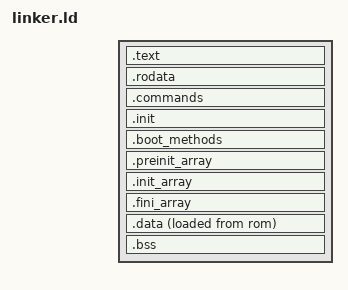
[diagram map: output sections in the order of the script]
INCLUDE generated/output_format.ld
ENTRY(_start)

INCLUDE generated/regions.ld

SECTIONS
{
	.text :
	{
		_ftext = .;
		/* ARM (Quicklogic EOS-S3, Gowin EMCU) interrupt vector tables use section name "isr_vector" */
		/* - such a table has to be placed at start */
		KEEP(*(.isr_vector))
		/* Make sure crt0 files come first, and they, and the isr */
		/* don't get disposed of by greedy optimisation */
		*crt0*(.text)
		KEEP(*crt0*(.text))
		KEEP(*(.text.isr))

		*(.text .stub .text.* .gnu.linkonce.t.*)
		_etext = .;
	} > rom

	.rodata :
	{
		. = ALIGN(8);
		_frodata = .;
		*(.rodata .rodata.* .gnu.linkonce.r.*)
		*(.rodata1)
		*(.srodata .srodata.*)
		*(.got .got.*)
		*(.toc .toc.*)

		/* Make sure the file is aligned on disk as well
		   as in memory; CRC calculation requires that. */
		FILL(0);
		. = ALIGN(8);
		_erodata = .;
	} > rom

	.commands :
	{
		PROVIDE_HIDDEN (__bios_cmd_start = .);
		KEEP(*(.bios_cmd))
		PROVIDE_HIDDEN (__bios_cmd_end = .);
	} > rom

	.init :
	{
		PROVIDE_HIDDEN (__bios_init_start = .);
		KEEP(*(.bios_init))
		PROVIDE_HIDDEN (__bios_init_end = .);
	} > rom

	.boot_methods :
	{
		PROVIDE_HIDDEN (__bios_boot_start = .);
		KEEP(*(.bios_boot))
		PROVIDE_HIDDEN (__bios_boot_end = .);
	} > rom

	.preinit_array :
	{
		. = ALIGN(8);
		PROVIDE_HIDDEN (__preinit_array_start = .);
		KEEP(*(SORT(.preinit_array.*)))
		KEEP(*(.preinit_array))
		PROVIDE_HIDDEN (__preinit_array_end = .);
	} > rom

	.init_array :
	{
		. = ALIGN(8);
		PROVIDE_HIDDEN (__init_array_start = .);
		KEEP(*(SORT(.init_array.*)))
		KEEP(*(.init_array))
		KEEP(*(SORT(.ctors.*)))
		KEEP(*(.ctors))
		PROVIDE_HIDDEN (__init_array_end = .);
	} > rom

	.fini_array :
	{
		. = ALIGN(8);
		PROVIDE_HIDDEN (__fini_array_start = .);
		KEEP(*(SORT(.fini_array.*)))
		KEEP(*(.fini_array))
		KEEP(*(SORT(.dtors.*)))
		KEEP(*(.dtors))
		PROVIDE_HIDDEN (__fini_array_end = .);
	} > rom

	.data :
	{
		. = ALIGN(8);
		_fdata = .;
		*(.data .data.* .gnu.linkonce.d.*)
		*(.data1)
		*(.sdata .sdata.* .gnu.linkonce.s.*)

		/* Make sure the file is aligned on disk as well
		   as in memory; CRC calculation requires that. */
		FILL(0);
		. = ALIGN(8);
		_edata = .;
	} > sram AT > rom

	.bss :
	{
		. = ALIGN(8);
		_fbss = .;
		*(.dynsbss)
		*(.sbss .sbss.* .gnu.linkonce.sb.*)
		*(.scommon)
		*(.dynbss)
		*(.bss .bss.* .gnu.linkonce.b.*)
		*(COMMON)
		. = ALIGN(8);
		_ebss = .;
		_end = .;
	} > sram

	/DISCARD/ :
	{
		*(.eh_frame)
		*(.comment)
	}
}

PROVIDE(_fstack = ORIGIN(sram) + LENGTH(sram));

PROVIDE(_fdata_rom = LOADADDR(.data));
PROVIDE(_edata_rom = LOADADDR(.data) + SIZEOF(.data));
